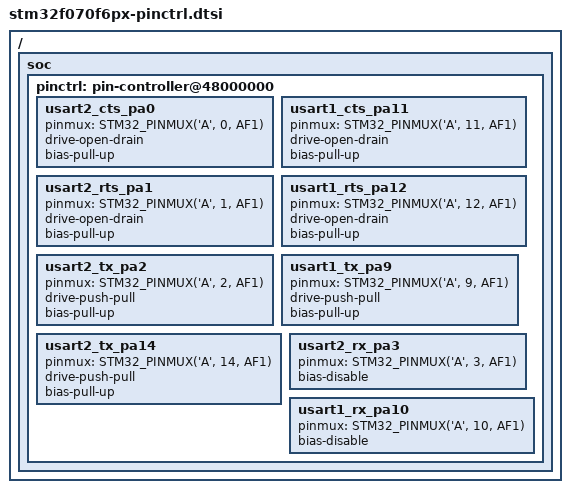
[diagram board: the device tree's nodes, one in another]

/*
 * NOTE: Autogenerated file using stm32_pinctrl_gen.py
 *
 * SPDX-License-Identifier: Apache-2.0
 */

#include <dt-bindings/pinctrl/stm32-pinctrl.h>

/ {
	soc {
		pinctrl: pin-controller@48000000 {
			/* UART_CTS */
			usart2_cts_pa0: usart2_cts_pa0 {
				pinmux = <STM32_PINMUX('A', 0, AF1)>;
				drive-open-drain;
				bias-pull-up;
			};

			usart1_cts_pa11: usart1_cts_pa11 {
				pinmux = <STM32_PINMUX('A', 11, AF1)>;
				drive-open-drain;
				bias-pull-up;
			};


			/* UART_RTS */
			usart2_rts_pa1: usart2_rts_pa1 {
				pinmux = <STM32_PINMUX('A', 1, AF1)>;
				drive-open-drain;
				bias-pull-up;
			};

			usart1_rts_pa12: usart1_rts_pa12 {
				pinmux = <STM32_PINMUX('A', 12, AF1)>;
				drive-open-drain;
				bias-pull-up;
			};


			/* UART_TX */
			usart2_tx_pa2: usart2_tx_pa2 {
				pinmux = <STM32_PINMUX('A', 2, AF1)>;
				drive-push-pull;
				bias-pull-up;
			};

			usart1_tx_pa9: usart1_tx_pa9 {
				pinmux = <STM32_PINMUX('A', 9, AF1)>;
				drive-push-pull;
				bias-pull-up;
			};

			usart2_tx_pa14: usart2_tx_pa14 {
				pinmux = <STM32_PINMUX('A', 14, AF1)>;
				drive-push-pull;
				bias-pull-up;
			};


			/* UART_RX */
			usart2_rx_pa3: usart2_rx_pa3 {
				pinmux = <STM32_PINMUX('A', 3, AF1)>;
				bias-disable;
			};

			usart1_rx_pa10: usart1_rx_pa10 {
				pinmux = <STM32_PINMUX('A', 10, AF1)>;
				bias-disable;
			};

		};
	};
};
